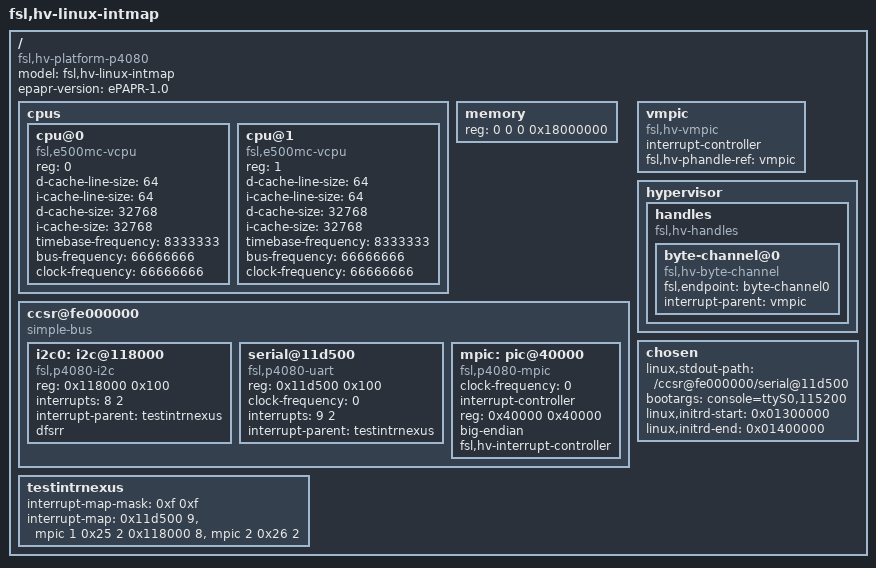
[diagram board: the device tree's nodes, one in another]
/*
 * Copyright (C) 2008,2009 Freescale Semiconductor, Inc.
 *
 * Redistribution and use in source and binary forms, with or without
 * modification, are permitted provided that the following conditions
 * are met:
 * 1. Redistributions of source code must retain the above copyright
 *    notice, this list of conditions and the following disclaimer.
 * 2. Redistributions in binary form must reproduce the above copyright
 *    notice, this list of conditions and the following disclaimer in the
 *    documentation and/or other materials provided with the distribution.
 *
 * THIS SOFTWARE IS PROVIDED BY THE AUTHOR "AS IS" AND ANY EXPRESS OR
 * IMPLIED WARRANTIES, INCLUDING, BUT NOT LIMITED TO, THE IMPLIED WARRANTIES
 * OF MERCHANTABILITY AND FITNESS FOR A PARTICULAR PURPOSE ARE DISCLAIMED.  IN
 * NO EVENT SHALL THE AUTHOR BE LIABLE FOR ANY DIRECT, INDIRECT, INCIDENTAL,
 * SPECIAL, EXEMPLARY, OR CONSEQUENTIAL DAMAGES (INCLUDING, BUT NOT LIMITED
 * TO, PROCUREMENT OF SUBSTITUTE GOODS OR SERVICES; LOSS OF USE, DATA, OR
 * PROFITS; OR BUSINESS INTERRUPTION) HOWEVER CAUSED AND ON ANY THEORY OF
 * LIABILITY, WHETHER IN CONTRACT, STRICT LIABILITY, OR TORT (INCLUDING
 * NEGLIGENCE OR OTHERWISE) ARISING IN ANY WAY OUT OF THE USE OF THIS
 * SOFTWARE, EVEN IF ADVISED OF THE POSSIBILITY OF SUCH DAMAGE.
 */

/dts-v1/;

/ {
	compatible = "fsl,hv-platform-p4080";
	model = "fsl,hv-linux-intmap";
	epapr-version = "ePAPR-1.0";
	#address-cells = <2>;
	#size-cells = <2>;

	cpus {
		#address-cells = <1>;
		#size-cells = <0>;

		cpu@0 {
			device_type = "cpu";
			compatible = "fsl,e500mc-vcpu";
			reg = <0>;
			d-cache-line-size = <64>;
			i-cache-line-size = <64>;
			d-cache-size = <32768>;
			i-cache-size = <32768>;
			timebase-frequency = <8333333>;
			bus-frequency = <66666666>;
			clock-frequency = <66666666>;
		};

		cpu@1 {
			device_type = "cpu";
			compatible = "fsl,e500mc-vcpu";
			reg = <1>;
			d-cache-line-size = <64>;
			i-cache-line-size = <64>;
			d-cache-size = <32768>;
			i-cache-size = <32768>;
			timebase-frequency = <8333333>;
			bus-frequency = <66666666>;
			clock-frequency = <66666666>;
		};
	};

	memory {
		reg = <0 0 0 0x18000000>;
		device_type = "memory";
	};

	ccsr@fe000000 {
		#address-cells = <1>;
		#size-cells = <1>;
		compatible = "simple-bus";
		device_type = "soc";
		ranges = <0 0 0xfe000000 0x400000>;

		i2c0: i2c@118000 {
			device_type = "i2c";
			compatible = "fsl,p4080-i2c",
			             "fsl,i2c", "fsl-i2c";
			reg = <0x118000 0x100>;
			interrupts = <8 2>;
			interrupt-parent = <&testintrnexus>;
			dfsrr;
		};

		serial@11d500 {		// UART2
			device_type = "serial";
			compatible = "fsl,p4080-uart",
				     "fsl,ns16550", "ns16550";
			reg = <0x11d500 0x100>;
			clock-frequency = <0>;
			interrupts = <9 2>;
			interrupt-parent = <&testintrnexus>;
		};

		mpic: pic@40000 {
			clock-frequency = <0>;
			interrupt-controller;
			#address-cells = <1>;
			#interrupt-cells = <2>;
			reg = <0x40000 0x40000>;
			compatible = "fsl,p4080-mpic", "fsl,mpic",
			             "chrp,open-pic";
			device_type = "open-pic";
			big-endian;
			fsl,hv-interrupt-controller;
		};
	};

	testintrnexus: testintrnexus {
		#address-cells = <1>;
		#interrupt-cells = <1>;
		interrupt-map-mask = <0xf 0xf>;
		interrupt-map = <
			0x11d500 9 &mpic 1 0x25 2
			0x118000 8 &mpic 2 0x26 2
		>;
	};

	vmpic:vmpic {
		compatible = "fsl,hv-vmpic";
		interrupt-controller;
		#address-cells = <0>;
		#interrupt-cells = <2>;
		fsl,hv-phandle-ref = <&vmpic>;
	};

	hypervisor {
		handles {
			#address-cells = <1>;
			#size-cells = <0>;
			compatible = "fsl,hv-handles";

			byte-channel@0 {
				compatible = "fsl,hv-byte-channel";
				fsl,endpoint = "byte-channel0";
				interrupt-parent = <&vmpic>;
			};
		};
	};

	chosen {
		linux,stdout-path = "/ccsr@fe000000/serial@11d500";
		bootargs = "console=ttyS0,115200";
		linux,initrd-start = <0x01300000>;
		linux,initrd-end = <0x01400000>;
	};
};
